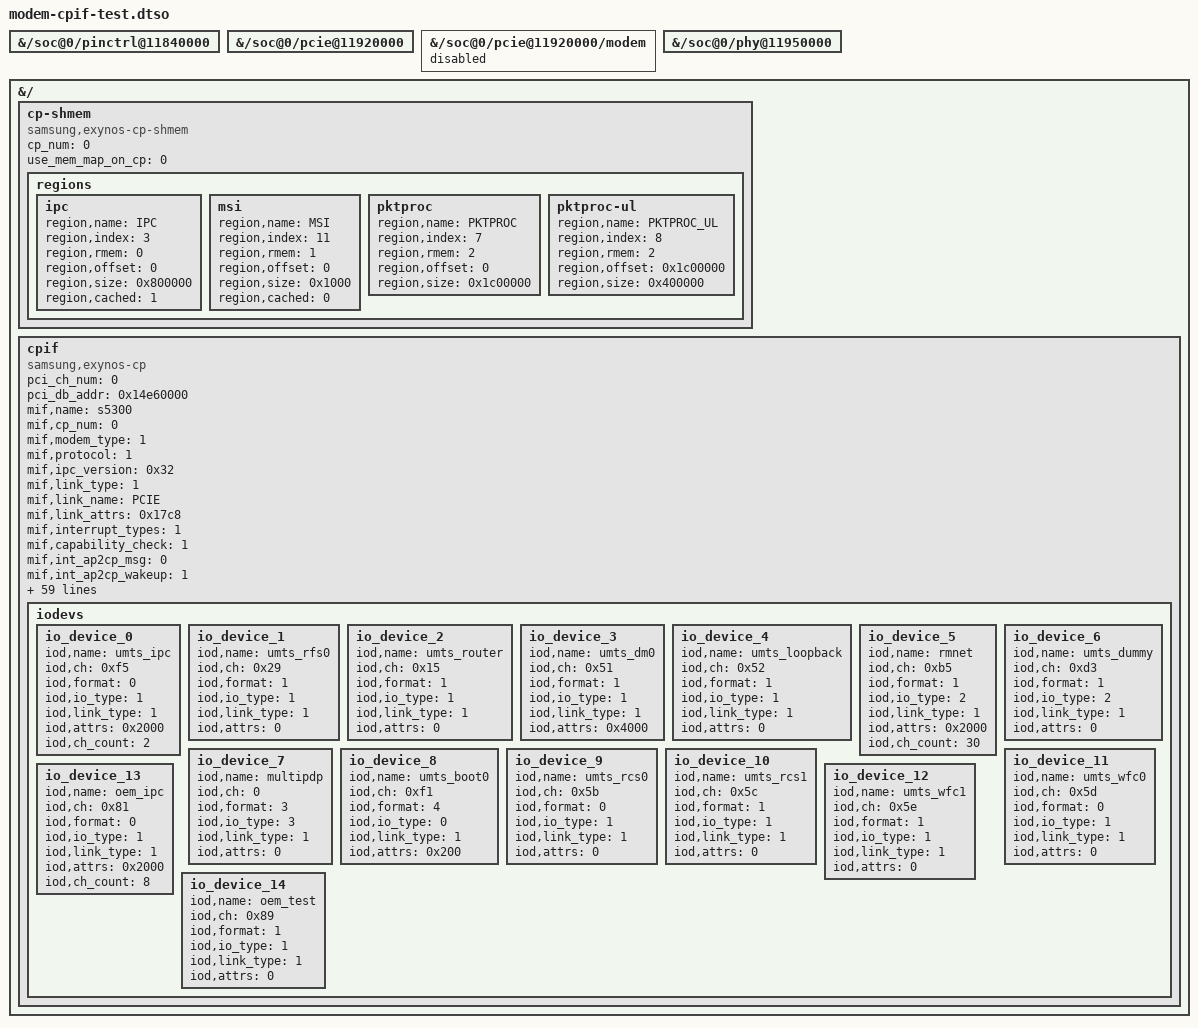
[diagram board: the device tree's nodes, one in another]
// SPDX-License-Identifier: MIT
/*
 * Bring-up only (MODEM-PLAN.md, stage M3.3): Google's modem interface driver
 * (CPIF, ported) on the S5300. Turns on the HSI1 pin controller, PCIe
 * GEN4A_0 and its PHY as modem-link-test does, and adds CPIF's two nodes
 * from stock's cpif and cp_shmem nodes, without what the port leaves out
 * (packet processor, throughput monitor, SPI boot, the AoC voice window).
 *
 * The modem's lines and shared memory stay described in the board's modem
 * node under the PCIe link. This overlay disables that node for the link
 * driver (pcie-gs201-cp then has no cp_on/cp_off and leaves the lines
 * alone), and CPIF takes the lines and the memory from it. Use it instead
 * of modem-link-test, never with it.
 *
 * Binding CPIF powers nothing: it drives the ap2cp outputs low (they are
 * low already, M0.4) and waits for cbd. cpif and shm_ipc are blacklisted
 * (omamobile-cpif.conf). Applied with fdtoverlay; paths, not labels, and no
 * references to base nodes, so the base DTB needs no __symbols__.
 */
/dts-v1/;
/plugin/;

&{/soc@0/pinctrl@11840000} {
	status = "okay";
};

&{/soc@0/pcie@11920000} {
	status = "okay";
};

&{/soc@0/pcie@11920000/modem} {
	status = "disabled";
};

&{/soc@0/phy@11950000} {
	status = "okay";
};

&{/} {
	cp-shmem {
		compatible = "samsung,exynos-cp-shmem";
		cp_num = <0>;
		use_mem_map_on_cp = <0>;

		/* region,rmem: the modem node's memory-region entries */
		regions {
			ipc {
				region,name = "IPC";
				region,index = <3>;
				region,rmem = <0>;
				region,offset = <0>;
				region,size = <0x800000>;
				region,cached = <1>;
			};

			msi {
				region,name = "MSI";
				region,index = <11>;
				region,rmem = <1>;
				region,offset = <0>;
				region,size = <0x1000>;
				region,cached = <0>;
			};

			pktproc {
				region,name = "PKTPROC";
				region,index = <7>;
				region,rmem = <2>;
				region,offset = <0>;
				region,size = <0x1c00000>;
			};

			pktproc-ul {
				region,name = "PKTPROC_UL";
				region,index = <8>;
				region,rmem = <2>;
				region,offset = <0x1c00000>;
				region,size = <0x400000>;
			};
		};
	};

	cpif {
		compatible = "samsung,exynos-cp";
		pci_ch_num = <0>;
		pci_db_addr = <0x14e60000>;
		mif,name = "s5300";
		mif,cp_num = <0>;
		mif,modem_type = <1>;
		mif,protocol = <1>;
		mif,ipc_version = <0x32>;
		mif,link_type = <1>;
		mif,link_name = "PCIE";
		mif,link_attrs = <0x17c8>;
		mif,interrupt_types = <1>;
		mif,capability_check = <1>;
		mif,int_ap2cp_msg = <0>;
		mif,int_ap2cp_wakeup = <1>;
		mif,int_ap2cp_status = <2>;
		mif,int_ap2cp_active = <3>;
		mif,int_ap2cp_lcd_status = <4>;
		mif,int_ap2cp_pcie_link_ack = <14>;
		mif,int_ap2cp_uart_noti = <15>;
		mif,irq_cp2ap_msg = <0>;
		mif,irq_cp2ap_status = <2>;
		mif,irq_cp2ap_active = <3>;
		mif,irq_cp2ap_wakelock = <8>;
		mif,irq_cp2ap_ratmode = <9>;
		mif,cp2ap_active_not_alive = <0>;
		legacy_fmt_head_tail_offset = <0x8>;
		legacy_fmt_buffer_offset = <0x1000>;
		legacy_fmt_txq_size = <0x1000>;
		legacy_fmt_rxq_size = <0x1000>;
		legacy_raw_head_tail_offset = <0x18>;
		legacy_raw_buffer_offset = <0x3000>;
		legacy_raw_txq_size = <0x1fd000>;
		legacy_raw_rxq_size = <0x200000>;
		legacy_raw_rx_buffer_cached = <0>;
		offset_srinfo_offset = <0x64>;
		offset_capability_offset = <0x70>;
		offset_boot_indicator = <0x90>;
		srinfo_offset = <0x400000>;
		srinfo_size = <0x300000>;
		capability_offset = <0xa0>;
		ap_capability_0 = <0>;
		ap_capability_1 = <0>;
		ap2cp_msg = <2 0x800>;
		cp2ap_msg = <2 0x804>;
		ap2cp_united_status = <2 0x808>;
		cp2ap_united_status = <2 0x80c>;
		ap2cp_kerneltime = <2 0x824>;
		ap2cp_handover_block_info = <2 0x82c>;
		sbi_lcd_status_mask = <0x1>;
		sbi_lcd_status_pos = <27>;
		sbi_crash_type_mask = <0xf>;
		sbi_crash_type_pos = <23>;
		sbi_uart_noti_mask = <0x1>;
		sbi_uart_noti_pos = <16>;
		sbi_ds_det_mask = <0x3>;
		sbi_ds_det_pos = <14>;
		sbi_pda_active_mask = <0x1>;
		sbi_pda_active_pos = <5>;
		sbi_ap_status_mask = <0xf>;
		sbi_ap_status_pos = <1>;
		sbi_cp_rat_mode_mask = <0x3f>;
		sbi_cp_rat_mode_pos = <26>;
		sbi_cp2ap_wakelock_mask = <0x1>;
		sbi_cp2ap_wakelock_pos = <6>;
		sbi_lte_active_mask = <0x1>;
		sbi_lte_active_pos = <5>;
		sbi_cp_status_mask = <0xf>;
		sbi_cp_status_pos = <1>;
		sbi_ap2cp_kerneltime_sec_mask = <0xfff>;
		sbi_ap2cp_kerneltime_sec_pos = <20>;
		sbi_ap2cp_kerneltime_usec_mask = <0xfffff>;
		sbi_ap2cp_kerneltime_usec_pos = <0>;
		pktproc_use_36bit_addr = <0>;

		iodevs {
			io_device_0 {
				iod,name = "umts_ipc";
				iod,ch = <0xf5>;
				iod,format = <0>;
				iod,io_type = <1>;
				iod,link_type = <1>;
				iod,attrs = <0x2000>;
				iod,ch_count = <2>;
			};

			io_device_1 {
				iod,name = "umts_rfs0";
				iod,ch = <0x29>;
				iod,format = <1>;
				iod,io_type = <1>;
				iod,link_type = <1>;
				iod,attrs = <0>;
			};

			io_device_2 {
				iod,name = "umts_router";
				iod,ch = <0x15>;
				iod,format = <1>;
				iod,io_type = <1>;
				iod,link_type = <1>;
				iod,attrs = <0>;
			};

			io_device_3 {
				iod,name = "umts_dm0";
				iod,ch = <0x51>;
				iod,format = <1>;
				iod,io_type = <1>;
				iod,link_type = <1>;
				iod,attrs = <0x4000>;
			};

			io_device_4 {
				iod,name = "umts_loopback";
				iod,ch = <0x52>;
				iod,format = <1>;
				iod,io_type = <1>;
				iod,link_type = <1>;
				iod,attrs = <0>;
			};

			io_device_5 {
				iod,name = "rmnet";
				iod,ch = <0xb5>;
				iod,format = <1>;
				iod,io_type = <2>;
				iod,link_type = <1>;
				iod,attrs = <0x2000>;
				iod,ch_count = <30>;
			};

			io_device_6 {
				iod,name = "umts_dummy";
				iod,ch = <0xd3>;
				iod,format = <1>;
				iod,io_type = <2>;
				iod,link_type = <1>;
				iod,attrs = <0>;
			};

			io_device_7 {
				iod,name = "multipdp";
				iod,ch = <0>;
				iod,format = <3>;
				iod,io_type = <3>;
				iod,link_type = <1>;
				iod,attrs = <0>;
			};

			io_device_8 {
				iod,name = "umts_boot0";
				iod,ch = <0xf1>;
				iod,format = <4>;
				iod,io_type = <0>;
				iod,link_type = <1>;
				iod,attrs = <0x200>;
			};

			io_device_9 {
				iod,name = "umts_rcs0";
				iod,ch = <0x5b>;
				iod,format = <0>;
				iod,io_type = <1>;
				iod,link_type = <1>;
				iod,attrs = <0>;
			};

			io_device_10 {
				iod,name = "umts_rcs1";
				iod,ch = <0x5c>;
				iod,format = <1>;
				iod,io_type = <1>;
				iod,link_type = <1>;
				iod,attrs = <0>;
			};

			io_device_11 {
				iod,name = "umts_wfc0";
				iod,ch = <0x5d>;
				iod,format = <0>;
				iod,io_type = <1>;
				iod,link_type = <1>;
				iod,attrs = <0>;
			};

			io_device_12 {
				iod,name = "umts_wfc1";
				iod,ch = <0x5e>;
				iod,format = <1>;
				iod,io_type = <1>;
				iod,link_type = <1>;
				iod,attrs = <0>;
			};

			io_device_13 {
				iod,name = "oem_ipc";
				iod,ch = <0x81>;
				iod,format = <0>;
				iod,io_type = <1>;
				iod,link_type = <1>;
				iod,attrs = <0x2000>;
				iod,ch_count = <8>;
			};

			io_device_14 {
				iod,name = "oem_test";
				iod,ch = <0x89>;
				iod,format = <1>;
				iod,io_type = <1>;
				iod,link_type = <1>;
				iod,attrs = <0>;
			};
		};
	};
};
